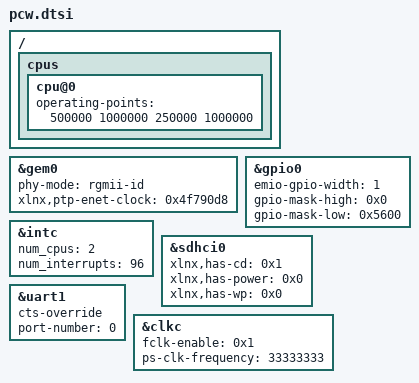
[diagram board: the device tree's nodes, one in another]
/*
 * CAUTION: This file is automatically generated by Xilinx.
 * Version: XSCT 2019.1
 * Today is: Tue May 21 21:04:32 2024
 */


/ {
	cpus {
		cpu@0 {
			operating-points = <500000 1000000 250000 1000000>;
		};
	};
};
&gem0 {
	phy-mode = "rgmii-id";
	status = "okay";
	xlnx,ptp-enet-clock = <0x4f790d8>;
};
&gpio0 {
	emio-gpio-width = <1>;
	gpio-mask-high = <0x0>;
	gpio-mask-low = <0x5600>;
};
&intc {
	num_cpus = <2>;
	num_interrupts = <96>;
};
&sdhci0 {
	status = "okay";
	xlnx,has-cd = <0x1>;
	xlnx,has-power = <0x0>;
	xlnx,has-wp = <0x0>;
};
&uart1 {
	cts-override ;
	device_type = "serial";
	port-number = <0>;
	status = "okay";
};
&clkc {
	fclk-enable = <0x1>;
	ps-clk-frequency = <33333333>;
};
